# STM32F423xx register map
File version: 1.0
Registers are 32-bit, read-write, reset 0x0 unless marked. A register's access mark holds for its fields unless they carry their own. Offsets are from the block's base; [hi:lo] are bit positions; {n}, {i} and the like mark numbered series.

## I2C1 — Inter-integrated Circuit Interface
Base 0x40005400
Same registers: I2C2 0x40005800, I2C3 0x40005C00
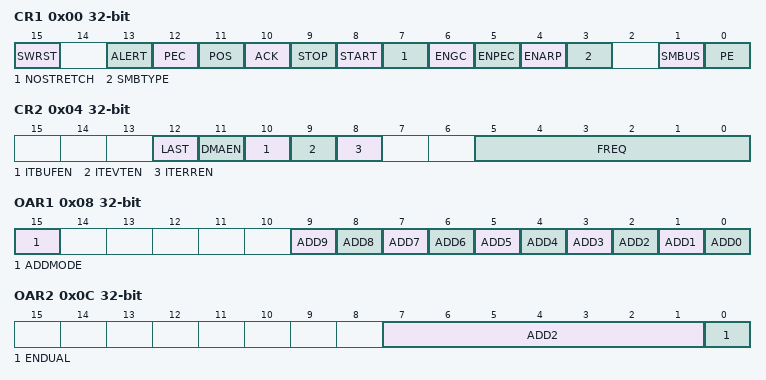
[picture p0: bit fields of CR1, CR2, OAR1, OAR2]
0x00 CR1 — I2C Control register 1
  [15] SWRST — Software Reset
  [13] ALERT — SMBus Alert
  [12] PEC — Packet Error Checking
  [11] POS — Acknowledge/PEC Position (for data reception)
  [10] ACK — Acknowledge Enable
    1=ACK (ACK is sent after current received byte.); 0=NACK (NACK is sent after current received byte.)
  [9] STOP — Stop Generation
  [8] START — Start Generation
  [7] NOSTRETCH — Clock Stretching Disable (Slave mode)
  [6] ENGC — General Call Enable
  [5] ENPEC — PEC Enable
  [4] ENARP — ARP Enable
  [3] SMBTYPE — SMBus Type
  [1] SMBUS — SMBus Mode
  [0] PE — Peripheral Enable
0x04 CR2 — I2C Control register 2
  [12] LAST — DMA Last Transfer
  [11] DMAEN — DMA Requests Enable
  [10] ITBUFEN — Buffer Interrupt Enable
  [9] ITEVTEN — Event Interrupt Enable
  [8] ITERREN — Error Interrupt Enable
  [5:0] FREQ — FREQ[5:0] bits (Peripheral Clock Frequency)
0x08 OAR1 — I2C Own address register 1
  [15] ADDMODE — Addressing Mode (Slave mode)
  [n] ADD{n} (n=0..9) — Bit {n}
0x0C OAR2 — I2C Own address register 2
  [7:1] ADD2 — Interface address
  [0] ENDUAL — Dual addressing mode enable
0x10 DR — I2C Data register
  [7:0] DR — 8-bit Data Register
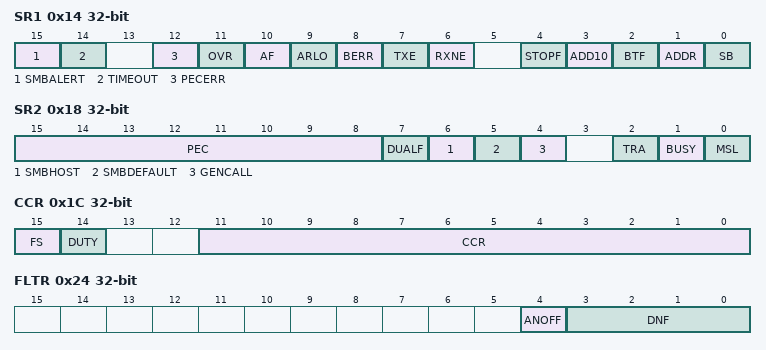
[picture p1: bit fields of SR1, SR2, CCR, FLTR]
0x14 SR1 — I2C Status register 1
  [15] SMBALERT — SMBus Alert
  [14] TIMEOUT — Timeout or Tlow Error
  [12] PECERR — PEC Error in reception
  [11] OVR — Overrun/Underrun
  [10] AF — Acknowledge Failure
  [9] ARLO — Arbitration Lost (master mode)
  [8] BERR — Bus Error
  [7] TXE — Data Register Empty (transmitters)
  [6] RXNE — Data Register not Empty (receivers)
  [4] STOPF — Stop detection (Slave mode)
  [3] ADD10 — 10-bit header sent (Master mode)
  [2] BTF — Byte Transfer Finished
  [1] ADDR — Address sent (master mode)/matched (slave mode)
  [0] SB — Start Bit (Master mode)
0x18 SR2 — I2C Status register 2
  [15:8] PEC — Packet Error Checking Register
  [7] DUALF — Dual Flag (Slave mode)
  [6] SMBHOST — SMBus Host Header (Slave mode)
  [5] SMBDEFAULT — SMBus Device Default Address (Slave mode)
  [4] GENCALL — General Call Address (Slave mode)
  [2] TRA — Transmitter/Receiver
    1=WRITE (Bus is in write transfer); 0=READ (Bus is in read transfer)
  [1] BUSY — Bus Busy
  [0] MSL — Master/Slave
0x1C CCR — I2C Clock control register
  [15] FS — I2C Master Mode Selection
    0=STANDARD_MODE (Master clock speed range is standard mode); 1=FAST_MODE (Master clock speed range is fast mode)
  [14] DUTY — Fast Mode Duty Cycle
    0=DUTYCYCLE_2 (I2C fast mode Tlow/Thigh = 2); 1=DUTYCYCLE_16_9 (I2C fast mode Tlow/Thigh = 16/9)
  [11:0] CCR — Clock Control Register in Fast/Standard mode (Master mode)
0x20 TRISE — I2C TRISE register
  [5:0] TRISE — Maximum Rise Time in Fast/Standard mode (Master mode)
0x24 FLTR — I2C FLTR register
  [4] ANOFF — Analog Noise Filter OFF
  [3:0] DNF — Digital Noise Filter

## FMPI2C1 — Inter-integrated Circuit Interface
Base 0x40006000
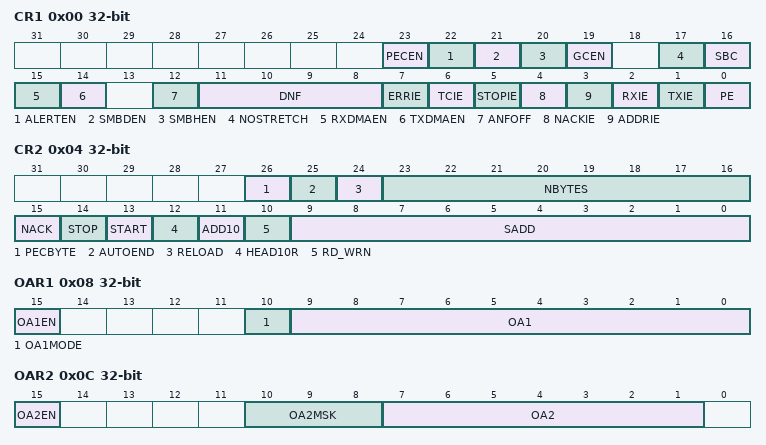
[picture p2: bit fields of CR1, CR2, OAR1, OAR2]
0x00 CR1 — FMPI2C Control register 1
  [23] PECEN — PEC enable
  [22] ALERTEN — SMBus alert enable
  [21] SMBDEN — SMBus device default address enable
  [20] SMBHEN — SMBus host address enable
  [19] GCEN — General call enable
  [17] NOSTRETCH — Clock stretching disable
  [16] SBC — Slave byte control
  [15] RXDMAEN — DMA reception requests enable
  [14] TXDMAEN — DMA transmission requests enable
  [12] ANFOFF — Analog noise filter OFF
  [11:8] DNF — Digital noise filter
  [7] ERRIE — Errors interrupt enable
  [6] TCIE — Transfer complete interrupt enable
  [5] STOPIE — STOP detection interrupt enable
  [4] NACKIE — NACK received interrupt enable
  [3] ADDRIE — Address match interrupt enable
  [2] RXIE — RX interrupt enable
  [1] TXIE — TX interrupt enable
  [0] PE — Peripheral enable
0x04 CR2 — FMPI2C Control register 2
  [26] PECBYTE — Packet error checking byte
  [25] AUTOEND — Automatic end mode (master mode)
  [24] RELOAD — NBYTES reload mode
  [23:16] NBYTES — Number of bytes
  [15] NACK — NACK generation (slave mode)
  [14] STOP — STOP generation (master mode)
  [13] START — START generation
  [12] HEAD10R — 10-bit address header only read direction (master mode)
  [11] ADD10 — 10-bit addressing mode (master mode)
  [10] RD_WRN — Transfer direction (master mode)
  [9:0] SADD — Slave address (master mode)
0x08 OAR1 — FMPI2C Own address 1 register
  [15] OA1EN — Own address 1 enable
  [10] OA1MODE — Own address 1 10-bit mode
  [9:0] OA1 — Interface own address 1
0x0C OAR2 — FMPI2C Own address 2 register
  [15] OA2EN — Own address 2 enable
  [10:8] OA2MSK — Own address 2 masks
  [7:1] OA2 — Interface own address 2
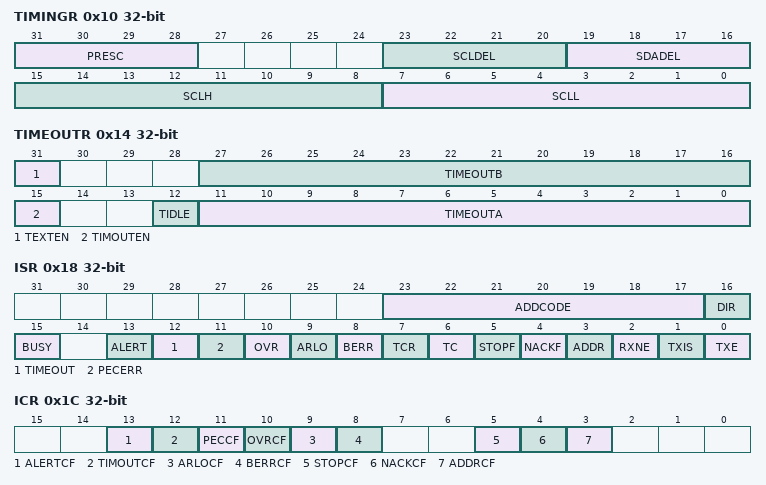
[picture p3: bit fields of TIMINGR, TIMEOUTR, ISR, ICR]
0x10 TIMINGR — FMPI2C Timing register
  [31:28] PRESC — Timings prescaler
  [23:20] SCLDEL — Data setup time
  [19:16] SDADEL — Data hold time
  [15:8] SCLH — SCL high period (master mode)
  [7:0] SCLL — SCL low period (master mode)
0x14 TIMEOUTR — FMPI2C Timeout register
  [31] TEXTEN — Extended clock timeout enable
  [27:16] TIMEOUTB — Bus timeout B
  [15] TIMOUTEN — Clock timeout enable
  [12] TIDLE — Idle clock timeout detection
  [11:0] TIMEOUTA — Bus timeout A
0x18 ISR — FMPI2C Interrupt and status register
  [23:17] ADDCODE — Address match code (slave mode)
  [16] DIR — Transfer direction (slave mode)
  [15] BUSY — Bus busy
  [13] ALERT — SMBus alert
  [12] TIMEOUT — Timeout or Tlow detection flag
  [11] PECERR — PEC error in reception
  [10] OVR — Overrun/Underrun
  [9] ARLO — Arbitration lost
  [8] BERR — Bus error
  [7] TCR — Transfer complete reload
  [6] TC — Transfer complete (master mode)
  [5] STOPF — STOP detection flag
  [4] NACKF — NACK received flag
  [3] ADDR — Address matched (slave mode)
  [2] RXNE — Receive data register not empty
  [1] TXIS — Transmit interrupt status
  [0] TXE — Transmit data register empty
0x1C ICR — FMPI2C Interrupt clear register
  [13] ALERTCF — Alert clear flag
  [12] TIMOUTCF — Timeout clear flag
  [11] PECCF — PAC error clear flag
  [10] OVRCF — Overrun/Underrun clear flag
  [9] ARLOCF — Arbitration lost clear flag
  [8] BERRCF — Bus error clear flag
  [5] STOPCF — STOP detection clear flag
  [4] NACKCF — NACK clear flag
  [3] ADDRCF — Address matched clear flag
0x20 PECR — FMPI2C PEC register
  [7:0] PEC
0x24 RXDR — FMPI2C Receive data register
  [7:0] RXDATA — 8-bit receive data
0x28 TXDR — FMPI2C Transmit data register
  [7:0] TXDATA — 8-bit transmit data
